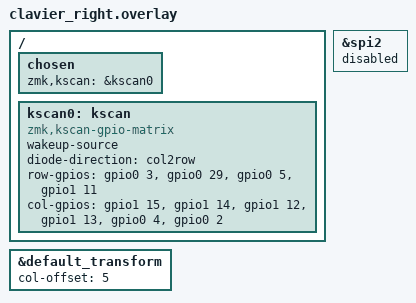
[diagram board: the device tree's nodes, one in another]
/*
 * Clavier 右手側オーバーレイ
 * - BLE Peripheral（左手側にワイヤレス接続する子機）
 * - 4行×6列 (合計24キー)
 *
 * 💡 このファイルの極意：
 * ────────────────────────────────────────────────────────────────────────
 * 1. ZMK Split仕様では、左右で同じマイコンを使うため、明示的に「お前は右手用だ」
 * と教えないと、左右両方が「左手（親機）」として暴走してしまいます。
 * 2. 最上部の / { chosen { ... } }; ノードで、このピン設定を右手として登録します。
 * 3. &default_transform { col-offset = <5>; }; によって、右手側のCol0〜5の信号を
 * 全体マトリクスの「6列目（インデックス5）以降」へカチッとスライド結合させます。
 * ────────────────────────────────────────────────────────────────────────
 */

#include "clavier.dtsi"

/ {
    /* ⚡【超重要】この設定ファイルは「右手側」のキースキャン（kscan0）であるとZMKに宣言 */
    chosen {
        zmk,kscan = &kscan0;
    };

    kscan0: kscan {
        compatible = "zmk,kscan-gpio-matrix";
        wakeup-source;
        diode-direction = "col2row";

        /* 右手側の行（Row）ピンアサイン */
        row-gpios
            = <&gpio0 3  (GPIO_ACTIVE_HIGH | GPIO_PULL_DOWN)>   /* Row0: P0.03 */
            , <&gpio0 29 (GPIO_ACTIVE_HIGH | GPIO_PULL_DOWN)>   /* Row1: P0.29 */
            , <&gpio0 5  (GPIO_ACTIVE_HIGH | GPIO_PULL_DOWN)>   /* Row2: P0.05 */
            , <&gpio1 11 (GPIO_ACTIVE_HIGH | GPIO_PULL_DOWN)>   /* Row3: P1.11 */
            ;

        /* 右手側の列（Col）ピンアサイン */
        col-gpios
            = <&gpio1 15 GPIO_ACTIVE_HIGH>   /* Col0: P1.15 → 結合マトリクスのCol5  */
            , <&gpio1 14 GPIO_ACTIVE_HIGH>   /* Col1: P1.14 → 結合マトリクスのCol6  */
            , <&gpio1 12 GPIO_ACTIVE_HIGH>   /* Col2: P1.12 → 結合マトリクスのCol7  */
            , <&gpio1 13 GPIO_ACTIVE_HIGH>   /* Col3: P1.13 → 結合マトリクスのCol8  */
            , <&gpio0 4  GPIO_ACTIVE_HIGH>   /* Col4: P0.04 → 結合マトリクスのCol9  */
            , <&gpio0 2  GPIO_ACTIVE_HIGH>   /* Col5: P0.02 → 結合マトリクスのCol10 */
            ;
    };
};

/* ⚡【超重要】右手側のトランスフォーム（住所録）を、左手側の5列分の後ろに結合させる命令 */
&default_transform {
    col-offset = <5>;
};

/* 左手側 SPI2 ピン（トラックボール用）を右手側 GPIO として使用するため明示的に無効化 */
&spi2 {
    status = "disabled";
};
